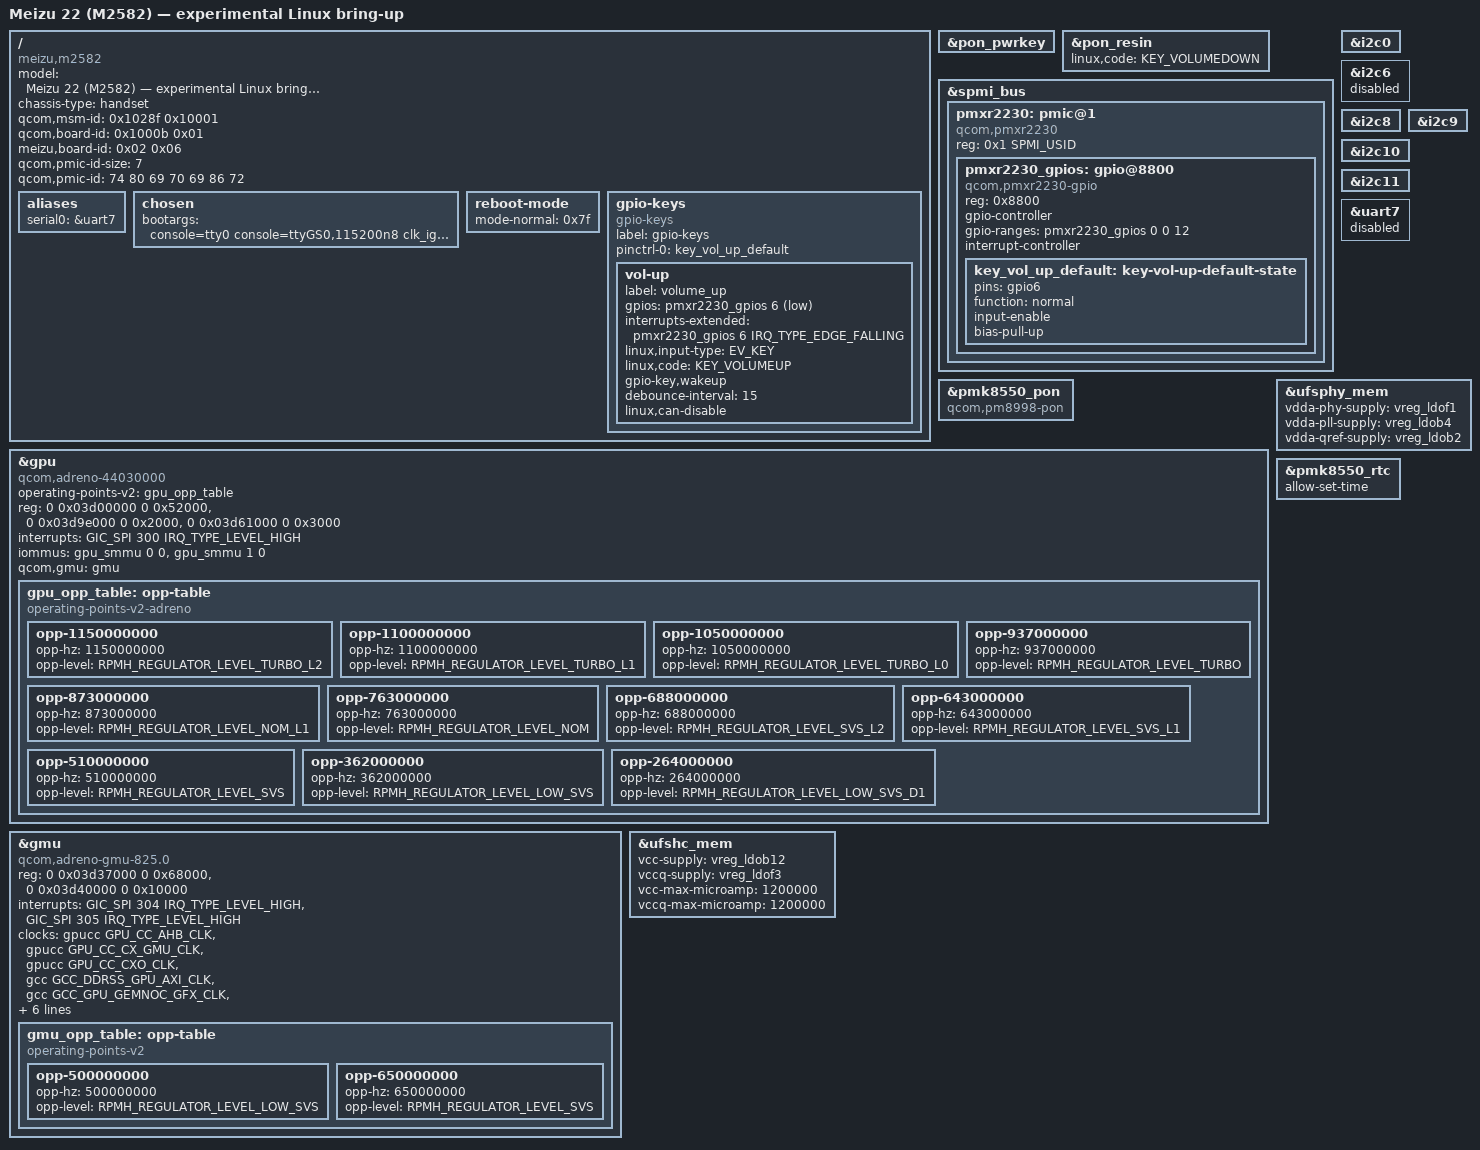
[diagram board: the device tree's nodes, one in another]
// SPDX-License-Identifier: BSD-3-Clause
/dts-v1/;
#include <dt-bindings/input/linux-event-codes.h>
#include "tuna.dtsi"
#include "meizu-m2582-memory.dtsi"
#include "meizu-m2582-power.dtsi"
#include "meizu-m2582-regulators.dtsi"
#include "tuna-display.dtsi"
#include "tuna-usb.dtsi"
#include "tuna-i2c.dtsi"
#include "meizu-m2582-i2c.dtsi"
/*
 * The PMK8550 sits on the SPMI bus declared in tuna.dtsi. This brings in the
 * PMIC node, its SDAM2 (whose restart-reason field the bootloader reads to pick
 * between Linux and fastboot) and the nvmem-reboot-mode node that writes it.
 *
 * It also adds the PMIC's PON, RTC, GPIO and PWM blocks. PON and PWM are
 * status = "disabled" upstream, and none of the four needs an RPMh regulator,
 * so this deliberately stays clear of the RPMh path that hangs this board.
 */
#include "pmk8550.dtsi"
/* 需要 &pmk8550 标签，必须放在 pmk8550.dtsi 之后 */
#include "meizu-m2582-vadc.dtsi"
/*
 * The rest of the PMIC complex this board carries. The factory tree puts
 * thirteen PMICs on the SPMI bus; PMK8550 at USID 0 and PMIH010X at USID 7
 * were already reachable, and this adds PM8550VE at USIDs 3, 5 and 6 and
 * PM8550VS at USID 9 -- what sm8750-pmics.dtsi describes for this SoC.
 *
 * Deliberately included for what it does not contain: no regulators.
 * Declaring a rail is what can reset this board, because the RPMh path
 * stalls the RSC; see meizu-m2582-power.dtsi. This adds only the PMICs, their
 * GPIO blocks and their thermal zones, so there is nothing that can take a
 * rail away.
 */
#include "sm8750-pmics.dtsi"
#include "pmd8028.dtsi"
#include "meizu-m2582-amoled.dtsi"
/* 需要 &spmi_bus 标签，必须放在 sm8750-pmics.dtsi 之后 */
#include "meizu-m2582-thermal.dtsi"

/ {
	model = "Meizu 22 (M2582) — experimental Linux bring-up";
	compatible = "meizu,m2582", "qcom,tuna";
	chassis-type = "handset";
	/* Live socinfo: SM8735 1.1, foundry 1, QRD platform 1.0. */
	qcom,msm-id = <0x1028f 0x10001>;
	qcom,board-id = <0x1000b 0x01>;
	/* ro.boot.proj_version=2, ro.boot.hw_version=6. */
	meizu,board-id = <0x02 0x06>;
	/* Live SMEM PMIC model order, no invented unused slots/revisions. */
	qcom,pmic-id-size = <7>;
	qcom,pmic-id = <74 80 69 70 69 86 72>;
	aliases { serial0 = &uart7; };
	chosen {
		bootargs = "console=tty0 console=ttyGS0,115200n8 clk_ignore_unused pd_ignore_unused cpuidle.off=1 rdinit=/init";
	};
};
/*
 * Merge a "normal" mode into the reboot-mode node pmk8550.dtsi creates.
 * Without it the kernel writes nothing on a plain reboot: the framework only
 * writes when the magic is non-zero, a plain reboot passes cmd == NULL, and
 * pmk8550.dtsi defines no mode for "normal" -- so the restart-reason field
 * kept the last fastboot value and every warm reset went back to fastboot.
 * Zero cannot be used either, since zero is what the framework refuses to
 * write.
 *
 * The SDAM2 field at offset 0x48 is seven bits wide (bits = <1 7>). Writing
 * 0x04 (0x02 << 1, "bootloader") enters fastboot 6 s later; writing 0xfe
 * (0x7f << 1) reaches Linux 18 s later, because ABL defaults to a normal boot
 * for a reason value it does not recognise and 0x7f is outside the set it
 * knows. mode-recovery (0x01) and mode-bootloader (0x02) come from
 * pmk8550.dtsi.
 */
/ {
	reboot-mode {
		mode-normal = <0x7f>;
	};
};

/*
 * The power and volume buttons.
 *
 * pmk8550.dtsi declares both of the PMK8550's PON inputs but leaves them
 * disabled, because not every board wires them to anything. This one does, and
 * they are the only input devices the board has: with them enabled
 * /sys/class/input stops being empty and the power button works as a real key
 * rather than resetting the board in hardware.
 *
 * pwrkey is the power button (KEY_POWER). resin is the volume-down line. Both
 * deliver events; both were confirmed with evtest.
 */
&pon_pwrkey {
	status = "okay";
};

&pon_resin {
	status = "okay";
	/*
	 * pmk8550.dtsi leaves the key code unset, so the driver's default is used
	 * and volume-down reports KEY_POWER, exactly like the power button. The
	 * factory tree gives it 114 (KEY_VOLUMEDOWN); measured on the board, the
	 * key does deliver events, it just delivered the wrong code.
	 */
	linux,code = <KEY_VOLUMEDOWN>;
};

/*
 * The volume-up button, and with it the PMXR2230.
 *
 * The factory device tree splits the buttons across two places. The power button
 * and volume-down are the PMK8550's PON inputs (pwrkey and resin, enabled
 * above). Volume-up is not on the PON at all: it hangs off GPIO 6 of the
 * PMXR2230, the PMIC at SPMI USID 1, active low with a pull-up.
 *
 * The PMXR2230 is the one part on this board that upstream has no binding for,
 * so its node is written out here. The GPIO controller itself needs nothing
 * new: pinctrl-spmi-gpio.c already lists "qcom,pmxr2230-gpio" with twelve
 * GPIOs. It is also the rail the two USB PHYs are fed from (ldob3), so having
 * it on the bus is worth something beyond the button.
 */
&spmi_bus {
	pmxr2230: pmic@1 {
		compatible = "qcom,pmxr2230", "qcom,spmi-pmic";
		reg = <0x1 SPMI_USID>;
		#address-cells = <1>;
		#size-cells = <0>;

		pmxr2230_gpios: gpio@8800 {
			compatible = "qcom,pmxr2230-gpio", "qcom,spmi-gpio";
			reg = <0x8800>;
			gpio-controller;
			gpio-ranges = <&pmxr2230_gpios 0 0 12>;
			#gpio-cells = <2>;
			interrupt-controller;
			#interrupt-cells = <2>;
		};
	};
};

&pmxr2230_gpios {
	/*
	 * Measured on the board: `in high normal vin-1 pull-up 30uA`, which is
	 * exactly what the button needs -- idle high, pulled low when pressed,
	 * matching GPIO_ACTIVE_LOW below.
	 *
	 * The factory tree also sets power-source = <1> on this pad. It is left
	 * out: the level reads correctly on the default supply, and adding it
	 * changed nothing measurable.
	 */
	key_vol_up_default: key-vol-up-default-state {
		pins = "gpio6";
		function = "normal";
		input-enable;
		bias-pull-up;
	};
};

/ {
	gpio-keys {
		compatible = "gpio-keys";
		label = "gpio-keys";

		pinctrl-names = "default";
		pinctrl-0 = <&key_vol_up_default>;

		vol-up {
			label = "volume_up";
			gpios = <&pmxr2230_gpios 6 GPIO_ACTIVE_LOW>;
			/*
			 * gpio-keys reads the level through gpiod and would take the
			 * interrupt from gpiod_to_irq() by default. Naming it here
			 * pins it to the pad's own interrupt rather than to whatever
			 * translation that call performs; on this PMIC GPIO the two
			 * turn out to be the same line ("spmi-gpio", irq 141), so
			 * this is belt and braces rather than a fix.
			 */
			interrupts-extended = <&pmxr2230_gpios 6 IRQ_TYPE_EDGE_FALLING>;
			linux,input-type = <EV_KEY>;
			linux,code = <KEY_VOLUMEUP>;
			gpio-key,wakeup;
			debounce-interval = <15>;
			linux,can-disable;
		};
	};
};

/*
 * The PON block, named the way this board names it.
 *
 * The factory tree calls the PON "qcom,pm8998-pon" with reg-names
 * "pon_hlos"/"pon_pbs", while upstream's pmk8550.dtsi calls it
 * "qcom,pmk8350-pon" with "hlos"/"pbs". The driver resolves its register
 * windows by reg-name, so the two spellings are not interchangeable; this
 * follows the factory, which is what the hardware on this board was described
 * by. The keys work with it -- pwrkey and resin both report events -- though
 * they also worked before this change was made, so it is alignment with the
 * vendor description rather than a proven fix.
 *
 * Only these properties are overridden; the children (pwrkey, resin) stay as
 * pmk8550.dtsi declares them.
 */
&pmk8550_pon {
	compatible = "qcom,pm8998-pon";
	reg-names = "pon_hlos", "pon_pbs";
};

/*
 * Bring the GENI I2C buses up.
 *
 * tuna-i2c.dtsi declares six of them (SE0-SE4 and SE6 in qupv3 wrap 1) but
 * leaves them disabled, since a bus with nothing on it is not free. Enabling
 * them costs nothing here and gives userspace /dev/i2c-N through I2C_CHARDEV,
 * which is what makes a bus probeable with i2cdetect.
 *
 * No pinctrl state is attached yet, so the SDA/SCL pads are still in their reset
 * configuration and traffic is not expected to work. The point of this step is
 * to confirm the controllers themselves probe; the pad configuration follows.
 */
/*
 * The GENI I2C buses stay disabled.
 *
 * Enabling them panics the board at 0.4 s, every boot, before userspace:
 *
 *     geni_i2c a80000.i2c: Bus frequency not specified, default to 100kHz.
 *     Internal error: synchronous external abort: 0000000096000010
 *     pc : geni_i2c_probe+0x2b4/0x534
 *
 * A synchronous external abort on a register access means the SE window is not
 * reachable at all, so the qupv3_1 wrapper needs something we have not given it.
 * Note that uart7, the only other block in that wrapper, is disabled and has
 * therefore never proved the wrapper works. The nodes in tuna-i2c.dtsi stay for
 * whoever picks this up; what they need is to be worked out first -- upstream's
 * geniqup nodes carry more than the two AHB clocks ours has -- rather than
 * guessed at with a probe that takes the whole board down.
 */

/*
 * Bring up one GENI I2C bus: SE0 at 0xa80000, not SE6.
 *
 * SE6 was the obvious pick -- the factory tree puts a WCD939x codec on SE3
 * and leaves SE6 free -- but SE6's register window does not exist as far as
 * the application processor is concerned. A single 4-byte read of 0xa98000
 * through /dev/mem returns BUS ERROR, so the kernel's first register access
 * after ioremap aborts with a synchronous external abort before any clock,
 * pinctrl or interconnect code runs. Five earlier attempts blamed the clock
 * numbers, the pin numbers, the interconnects and a closed GCC block; none of
 * them could have worked, because the window itself never answers.
 *
 * SE0 is reachable (0xa80000 reads 0x00000009) and its pads are on gpio52/53.
 * SE1 and SE6 are the only dead windows in wrap 1 -- measured, not guessed.
 */

/*
 * The GPU. This board's part is an Adreno 825, chip id 0x44030000, which the
 * factory device tree names "qcom,adreno-gpu-gen8-6-0" with gpu-model
 * "Adreno825".
 *
 * The first compatible must carry the chip id as eight hex digits. Mainline's
 * find_chipid() parses either "qcom,adreno-<major>.<minor>" or
 * "qcom,adreno-<8 hex digits>" and understands nothing else, so the vendor's
 * string would send it to the legacy qcom,chipid property -- and that path
 * returns NULL from adreno_info() for this part until the a8xx catalog carries
 * an entry for 0x44030000, which now it does. Without that entry
 * adreno_has_gpu() is false, no GPU platform device is created, and the only
 * symptom is "no GPU device was found".
 *
 * Register windows come from the vendor node and are collapsed to the three
 * mainline consumes:
 *   0x3d00000 + 0x52000   the GPU block, covering CUDA 0x50000 (RSCC), which on
 *                         a8xx mainline addresses as a fixed offset inside this
 *                         same window rather than as its own region
 *   0x3d9e000 + 0x2000    cx_mem
 *   0x3d61000 + 0x3000    cx_dbgc
 * The vendor's separate qdss_gfx/qdss_etr/qdss_tmc windows are not carried
 * over: the coresight nodes already claim those addresses, and they are
 * debug-only.
 *
 * qcom,gmu is mandatory and a6xx_gpu_init() BUG_ON()s without it -- it is not
 * an optional link.
 */
&gpu {
	compatible = "qcom,adreno-44030000", "qcom,adreno";
	/*
	 * Re-enabled after the GMU got its own OPP table. The previous attempt
	 * hung during the DRM probe and took the USB gadget with it, and the GMU
	 * OPP error was the last thing reported before that, so this is the fix
	 * for the step that failed.
	 *
	 * Note that the vendor node declares no vdd or vddcx either, so the two
	 * "supply not found, using dummy regulator" lines are normal and were not
	 * the cause; the vendor GMU's power domains are exactly the three
	 * declared on &gmu (gpu_cc_cx_gdsc, gpu_cc_cx_gmu_gdsc, gx_clkctl's GX
	 * rail), and the GPU core is parented through the GMU rather than
	 * declaring a rail of its own.
	 */
	status = "okay";

	operating-points-v2 = <&gpu_opp_table>;


	reg = <0 0x03d00000 0 0x52000>,
	      <0 0x03d9e000 0 0x2000>,
	      <0 0x03d61000 0 0x3000>;
	reg-names = "kgsl_3d0_reg_memory",
		    "cx_mem",
		    "cx_dbgc";

	interrupts = <GIC_SPI 300 IRQ_TYPE_LEVEL_HIGH>;

	iommus = <&gpu_smmu 0 0>,
		 <&gpu_smmu 1 0>;

	qcom,gmu = <&gmu>;

	/*
	 * GPU DVFS table. Frequencies, RPMh corner levels and ACD levels are the
	 * vendor's own power levels from power-levels@0 of the factory device tree's
	 * kgsl node; the highest is 1150 MHz, which is also the vendor's default
	 * (qcom,initial-pwrlevel = 10 into an 11-entry table).
	 *
	 * opp-level values are the vendor's qcom,level words and each one lands exactly
	 * on an RPMH_REGULATOR_LEVEL_* constant, which is what they are: 0x1b0 is
	 * TURBO_L2, down to 0x38 which is LOW_SVS_D1.
	 *
	 * opp-peak-kBps and qcom,opp-acd-level are deliberately absent for now. The
	 * first needs the GPU's interconnect path wired up, and the second is consumed
	 * by the ACD code, which is a later stage. Leaving them out keeps this table to
	 * the two things the probe needs -- a frequency to pick and a level to vote --
	 * so that if the GPU still fails to come up the cause is not ambiguous.
	 */
	gpu_opp_table: opp-table {
		compatible = "operating-points-v2-adreno", "operating-points-v2";

		opp-1150000000 {
			opp-hz = /bits/ 64 <1150000000>;
			opp-level = <RPMH_REGULATOR_LEVEL_TURBO_L2>;
		};

		opp-1100000000 {
			opp-hz = /bits/ 64 <1100000000>;
			opp-level = <RPMH_REGULATOR_LEVEL_TURBO_L1>;
		};

		opp-1050000000 {
			opp-hz = /bits/ 64 <1050000000>;
			opp-level = <RPMH_REGULATOR_LEVEL_TURBO_L0>;
		};

		opp-937000000 {
			opp-hz = /bits/ 64 <937000000>;
			opp-level = <RPMH_REGULATOR_LEVEL_TURBO>;
		};

		opp-873000000 {
			opp-hz = /bits/ 64 <873000000>;
			opp-level = <RPMH_REGULATOR_LEVEL_NOM_L1>;
		};

		opp-763000000 {
			opp-hz = /bits/ 64 <763000000>;
			opp-level = <RPMH_REGULATOR_LEVEL_NOM>;
		};

		opp-688000000 {
			opp-hz = /bits/ 64 <688000000>;
			opp-level = <RPMH_REGULATOR_LEVEL_SVS_L2>;
		};

		opp-643000000 {
			opp-hz = /bits/ 64 <643000000>;
			opp-level = <RPMH_REGULATOR_LEVEL_SVS_L1>;
		};

		opp-510000000 {
			opp-hz = /bits/ 64 <510000000>;
			opp-level = <RPMH_REGULATOR_LEVEL_SVS>;
		};

		opp-362000000 {
			opp-hz = /bits/ 64 <362000000>;
			opp-level = <RPMH_REGULATOR_LEVEL_LOW_SVS>;
		};

		opp-264000000 {
			opp-hz = /bits/ 64 <264000000>;
			opp-level = <RPMH_REGULATOR_LEVEL_LOW_SVS_D1>;
		};
	};
};

/*
 * The GMU. A sibling of the GPU node, not a child: the vendor tree has it at
 * 0x3d37000 and mainline looks it up through the GPU's qcom,gmu phandle, so
 * both have to be real platform devices.
 *
 * reg index 0 is what a6xx_gmu_get_mmio() maps as the GMU base; the vendor's
 * second window ("gmu_ao_blk_dec0") is not one mainline names. On a8xx mainline
 * takes RSCC as gpu->mmio + 0x50000 rather than from here, so no rscc region is
 * needed in this node.
 *
 * Power domain names follow mainline's binding: "cx", "gmu", "gx", in that
 * order, matching gpu_cc_cx_gdsc, gpu_cc_cx_gmu_gdsc and gx_clkctl_gx_gdsc.
 */
&gmu {
	compatible = "qcom,adreno-gmu-825.0", "qcom,adreno-gmu";
	status = "okay";

	reg = <0 0x03d37000 0 0x68000>,
	      <0 0x03d40000 0 0x10000>;
	reg-names = "gmu", "gmu_ao_blk_dec0";

	interrupts = <GIC_SPI 304 IRQ_TYPE_LEVEL_HIGH>,
		     <GIC_SPI 305 IRQ_TYPE_LEVEL_HIGH>;
	interrupt-names = "hfi", "gmu";

	/*
	 * Note "axi": GCC_DDRSS_GPU_AXI_CLK. It was missing here, and it is the
	 * one entry in this list the vendor's GMU node has that ours did not --
	 * the vendor's clock list is
	 *   <&gpucc 0x05> CX_GMU, <&gpucc 0x07> CXO, <&gcc 0x12> DDRSS_GPU_AXI,
	 *   <&gcc 0x22> GEMNOC_GFX, <&gpucc 0x02> AHB, <&gpucc 0x12> HUB_CX_INT
	 * with names gmu_clk, cxo_clk, axi_clk, memnoc_clk, ahb_clk, hub_clk, and
	 * sm8650's node carries the same seven clocks including "axi". Without
	 * the GPU's AXI clock the GMU cannot reach the bus, which is consistent
	 * with firmware loading but the M3 never reporting back.
	 */
	clocks = <&gpucc GPU_CC_AHB_CLK>,
		 <&gpucc GPU_CC_CX_GMU_CLK>,
		 <&gpucc GPU_CC_CXO_CLK>,
		 <&gcc GCC_DDRSS_GPU_AXI_CLK>,
		 <&gcc GCC_GPU_GEMNOC_GFX_CLK>,
		 <&gpucc GPU_CC_HUB_CX_INT_CLK>,
		 <&gpucc GPU_CC_DEMET_CLK>;
	clock-names = "ahb", "gmu", "cxo", "axi", "memnoc", "hub", "demet";

	/*
	 * Two domains, not the three the factory device tree lists.
	 *
	 * The factory node says power-domain-names = "cx", "gmu_cx", "gx" with
	 * <&gpucc 0>, <&gpucc 2>, <&gxclkctl 0>. GX is dropped here, and that
	 * was established by experiment rather than by reading: with GX present
	 * the board wedges on every attempt, and the wedge takes the USB
	 * controller with it so it needs a physical power cycle. Removing it
	 * lets the GPU reach firmware loading. That was re-tested after
	 * gxclkctl's own node was corrected to the SoC's single CX GDSC, in
	 * case the earlier wedge had really been that node's fault -- it still
	 * wedged, so GX on this node is genuinely the trigger.
	 *
	 * The reason is visible in gdsc_gx_do_nothing_enable(): the GX rail is
	 * not the CPU's to raise, the GMU does it, and the CPU-side GDSC exists
	 * so power-down can force the domain really off. Listing it here tells
	 * genpd the opposite -- that the GMU may not run until GX is up -- so
	 * probe-time sequencing tries to raise a rail whose bring-up belongs to
	 * firmware that has not started. GX stays out; the GMU brings it up.
	 */
	power-domains = <&gpucc GPU_CC_CX_GDSC>,
			<&gpucc GPU_CC_CX_GMU_GDSC>;
	power-domain-names = "cx", "gmu";

	iommus = <&gpu_smmu 5 0>;

	operating-points-v2 = <&gmu_opp_table>;

	/*
	 * The GMU handles its own frequency switching and a6xx_gmu_pwrlevels_probe()
	 * requires this table -- without it the probe fails outright ("Unable to set
	 * the OPP table for the GMU"), which is one of the two errors that were
	 * visible before the first power-up hang.
	 *
	 * Frequencies and levels are the vendor's own qcom,gmu-freq-table from the
	 * factory GMU node: <0x1dcd6500 0x40 0x26be3680 0x80>, i.e. 500 MHz at
	 * RPMH level 0x40 (LOW_SVS) and 650 MHz at 0x80 (SVS). The vendor boots at
	 * the first of the pair (qcom,gpu-gmu-perf-ddr-bw sits alongside it).
	 */
	gmu_opp_table: opp-table {
		compatible = "operating-points-v2";

		opp-500000000 {
			opp-hz = /bits/ 64 <500000000>;
			opp-level = <RPMH_REGULATOR_LEVEL_LOW_SVS>;
		};

		opp-650000000 {
			opp-hz = /bits/ 64 <650000000>;
			opp-level = <RPMH_REGULATOR_LEVEL_SVS>;
		};
	};
};

&i2c0 { status = "okay"; };

/* SE6 stays disabled: enabling it panics the board, see above. */
&i2c6 { status = "disabled"; };

/*
 * The four buses that carry the board's I2C devices, from the vendor overlay
 * (see meizu-m2582-i2c.dtsi for how that overlay was identified and why every
 * constant in it could be cross-checked). Brought up one step at a time: the
 * controllers first, with no child devices declared, so a probe failure is
 * attributable to the bus and nothing above it. The devices follow once each
 * address has been seen answering on the wire.
 */
&i2c8 { status = "okay"; };
&i2c9 { status = "okay"; };
&i2c10 { status = "okay"; };
&i2c11 { status = "okay"; };

/* Ordinary USB cable diagnostics: keep the unconnected UART disabled. */

&uart7 { status = "disabled"; };
&ufsphy_mem {
	vdda-phy-supply = <&vreg_ldof1>;
	vdda-pll-supply = <&vreg_ldob4>;
	vdda-qref-supply = <&vreg_ldob2>;
	status = "okay";
};
&ufshc_mem {
	vcc-supply = <&vreg_ldob12>;
	vccq-supply = <&vreg_ldof3>;
	vcc-max-microamp = <1200000>;
	vccq-max-microamp = <1200000>;
	status = "okay";
};

/*
 * Let userspace set the RTC.
 *
 * rtc-pm8xxx refuses RTC_SET_TIME unless the node says so, and the failure is
 * opaque: hwclock reports "ioctl(RTC_SET_TIME) to /dev/rtc0 to set the time
 * failed: No such device", which reads like a missing device rather than a
 * permission flag. Measured on the board: rtc0 registers and RTC_HCTOSYS pulls
 * the system clock from it, but the clock itself sits at 1970-11-29 until this
 * is set.
 */
&pmk8550_rtc {
	allow-set-time;
};
